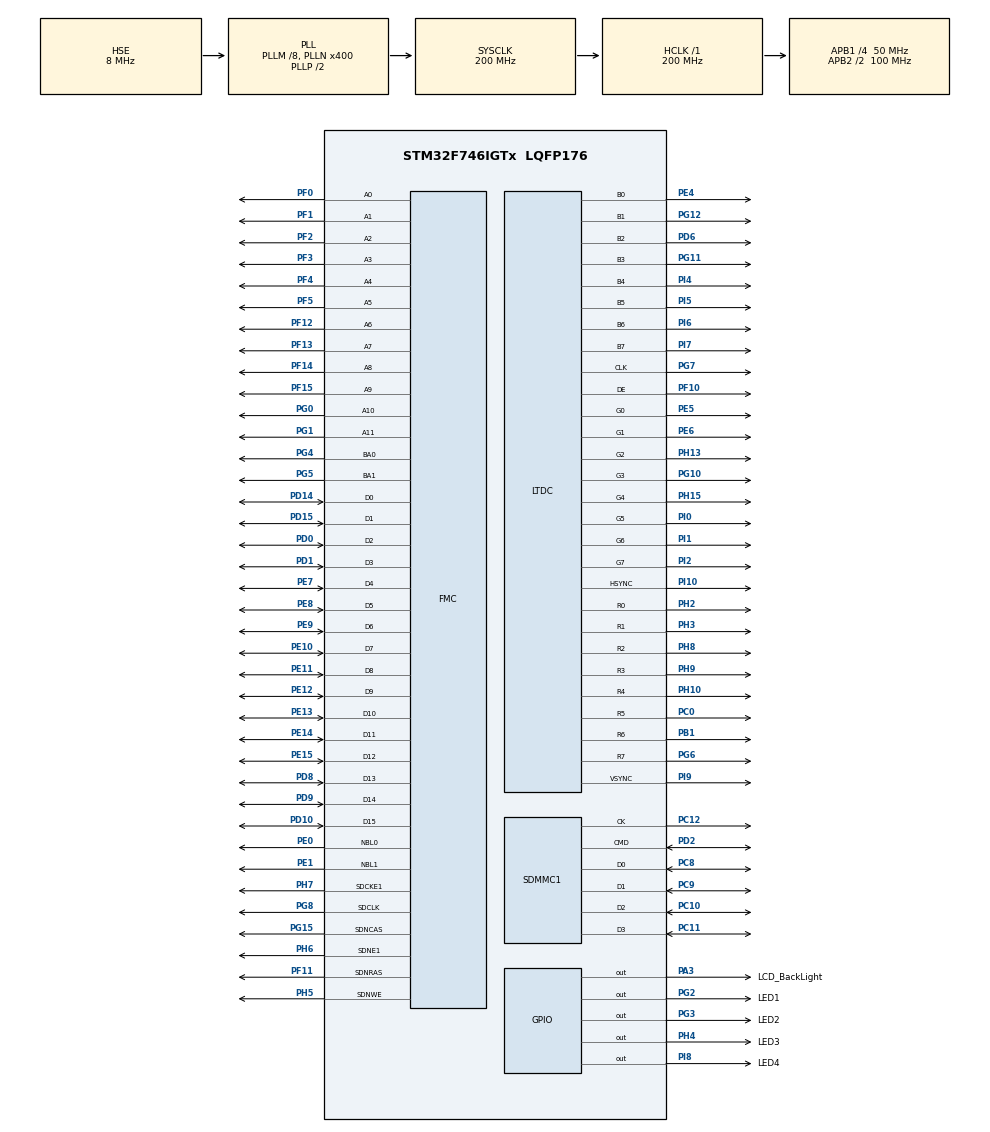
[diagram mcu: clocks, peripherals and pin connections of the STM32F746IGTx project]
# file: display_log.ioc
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CORTEX_M7.AccessPermission-Cortex_Memory_Protection_Unit_Region0_Settings=MPU_REGION_FULL_ACCESS
CORTEX_M7.BaseAddress-Cortex_Memory_Protection_Unit_Region0_Settings=0x20010000
CORTEX_M7.CPU_DCache=Enabled
CORTEX_M7.CPU_ICache=Enabled
CORTEX_M7.Enable-Cortex_Memory_Protection_Unit_Region0_Settings=MPU_REGION_ENABLE
CORTEX_M7.IsCacheable-Cortex_Memory_Protection_Unit_Region0_Settings=MPU_ACCESS_CACHEABLE
CORTEX_M7.MPU_Control=MPU_PRIVILEGED_DEFAULT
CORTEX_M7.Size-Cortex_Memory_Protection_Unit_Region0_Settings=MPU_REGION_SIZE_256KB
CORTEX_M7.SubRegionDisable-Cortex_Memory_Protection_Unit_Region0_Settings=0x0
DMA2D.ColorMode=DMA2D_OUTPUT_RGB565
Dma.MEMTOMEM.0.Direction=DMA_MEMORY_TO_MEMORY
Dma.MEMTOMEM.0.FIFOMode=DMA_FIFOMODE_ENABLE
Dma.MEMTOMEM.0.FIFOThreshold=DMA_FIFO_THRESHOLD_FULL
Dma.MEMTOMEM.0.Instance=DMA2_Stream0
Dma.MEMTOMEM.0.MemBurst=DMA_MBURST_SINGLE
Dma.MEMTOMEM.0.MemDataAlignment=DMA_MDATAALIGN_HALFWORD
Dma.MEMTOMEM.0.MemInc=DMA_MINC_ENABLE
Dma.MEMTOMEM.0.Mode=DMA_NORMAL
Dma.MEMTOMEM.0.PeriphBurst=DMA_PBURST_SINGLE
Dma.MEMTOMEM.0.PeriphDataAlignment=DMA_PDATAALIGN_HALFWORD
Dma.MEMTOMEM.0.PeriphInc=DMA_PINC_ENABLE
Dma.MEMTOMEM.0.Priority=DMA_PRIORITY_HIGH
Dma.Request0=MEMTOMEM
FATFS._MAX_SS=4096
FMC.CASLatency1=FMC_SDRAM_CAS_LATENCY_3
FMC.ExitSelfRefreshDelay1=7
FMC.LoadToActiveDelay1=2
FMC.RCDDelay1=2
FMC.RPDelay1=2
FMC.RPDelay2=2
FMC.ReadPipeDelay1=FMC_SDRAM_RPIPE_DELAY_1
FMC.ReadPipeDelay2=FMC_SDRAM_RPIPE_DELAY_1
FMC.RowBitsNumber1=FMC_SDRAM_ROW_BITS_NUM_12
FMC.RowCycleDelay1=6
FMC.RowCycleDelay2=6
FMC.SDClockPeriod1=FMC_SDRAM_CLOCK_PERIOD_2
FMC.SDClockPeriod2=FMC_SDRAM_CLOCK_PERIOD_2
FMC.SelfRefreshTime1=4
FMC.WriteRecoveryTime1=2
LTDC.ActiveH=600
LTDC.ActiveW=1024
LTDC.Alpha_L0=0xFF
LTDC.Alpha_L1=0
LTDC.BlendingFactor1_L0=LTDC_BLENDING_FACTOR1_PAxCA
LTDC.BlendingFactor1_L1=LTDC_BLENDING_FACTOR1_PAxCA
LTDC.BlendingFactor2_L0=LTDC_BLENDING_FACTOR2_PAxCA
LTDC.BlendingFactor2_L1=LTDC_BLENDING_FACTOR2_PAxCA
LTDC.FBStartAdress_L0=0xD0000000
LTDC.FBStartAdress_L1=0xD0200000
LTDC.HBP=140
LTDC.HFP=160
LTDC.HSync=20
LTDC.ImageHeight_L0=600
LTDC.ImageHeight_L1=600
LTDC.ImageWidth_L0=1024
LTDC.ImageWidth_L1=1024
LTDC.PixelFormat_L0=LTDC_PIXEL_FORMAT_RGB565
LTDC.PixelFormat_L1=LTDC_PIXEL_FORMAT_RGB565
LTDC.VBP=20
LTDC.VFP=12
LTDC.VSync=3
LTDC.WindowX1_L0=1024
LTDC.WindowX1_L1=1024
LTDC.WindowY1_L0=600
LTDC.WindowY1_L1=600
Mcu.Family=STM32F7
Mcu.Name=STM32F746IGTx
Mcu.Package=LQFP176
NVIC.PriorityGroup=NVIC_PRIORITYGROUP_4
PA3.GPIO_Label=LCD_BackLight
PA3.Signal=GPIO_Output
PB1.GPIO_Speed=GPIO_SPEED_FREQ_VERY_HIGH
PB1.Mode=RGB888
PB1.Signal=LTDC_R6
PC0.GPIO_Speed=GPIO_SPEED_FREQ_VERY_HIGH
PC0.Mode=RGB888
PC0.Signal=LTDC_R5
PC10.Mode=SD_4_bits_Wide_bus
PC10.Signal=SDMMC1_D2
PC11.Mode=SD_4_bits_Wide_bus
PC11.Signal=SDMMC1_D3
PC12.Mode=SD_4_bits_Wide_bus
PC12.Signal=SDMMC1_CK
PC8.Mode=SD_4_bits_Wide_bus
PC8.Signal=SDMMC1_D0
PC9.Mode=SD_4_bits_Wide_bus
PC9.Signal=SDMMC1_D1
PD0.Signal=FMC_D2_DA2
PD1.Signal=FMC_D3_DA3
PD10.Signal=FMC_D15_DA15
PD14.Signal=FMC_D0_DA0
PD15.Signal=FMC_D1_DA1
PD2.Mode=SD_4_bits_Wide_bus
PD2.Signal=SDMMC1_CMD
PD6.GPIO_Speed=GPIO_SPEED_FREQ_VERY_HIGH
PD6.Mode=RGB888
PD6.Signal=LTDC_B2
PD8.Signal=FMC_D13_DA13
PD9.Signal=FMC_D14_DA14
PE0.Signal=FMC_NBL0
PE1.Signal=FMC_NBL1
PE10.Signal=FMC_D7_DA7
PE11.Signal=FMC_D8_DA8
PE12.Signal=FMC_D9_DA9
PE13.Signal=FMC_D10_DA10
PE14.Signal=FMC_D11_DA11
PE15.Signal=FMC_D12_DA12
PE4.GPIO_Speed=GPIO_SPEED_FREQ_VERY_HIGH
PE4.Mode=RGB888
PE4.Signal=LTDC_B0
PE5.GPIO_Speed=GPIO_SPEED_FREQ_VERY_HIGH
PE5.Mode=RGB888
PE5.Signal=LTDC_G0
PE6.GPIO_Speed=GPIO_SPEED_FREQ_VERY_HIGH
PE6.Mode=RGB888
PE6.Signal=LTDC_G1
PE7.Signal=FMC_D4_DA4
PE8.Signal=FMC_D5_DA5
PE9.Signal=FMC_D6_DA6
PF0.Signal=FMC_A0
PF1.Signal=FMC_A1
PF10.GPIO_Speed=GPIO_SPEED_FREQ_VERY_HIGH
PF10.Mode=RGB888
PF10.Signal=LTDC_DE
PF11.Signal=FMC_SDNRAS
PF12.Signal=FMC_A6
PF13.Signal=FMC_A7
PF14.Signal=FMC_A8
PF15.Signal=FMC_A9
PF2.Signal=FMC_A2
PF3.Signal=FMC_A3
PF4.Signal=FMC_A4
PF5.Signal=FMC_A5
PG0.Signal=FMC_A10
PG1.Signal=FMC_A11
PG10.GPIO_Speed=GPIO_SPEED_FREQ_VERY_HIGH
PG10.Mode=RGB888
PG10.Signal=LTDC_G3
PG11.GPIO_Speed=GPIO_SPEED_FREQ_VERY_HIGH
PG11.Mode=RGB888
PG11.Signal=LTDC_B3
PG12.GPIO_Speed=GPIO_SPEED_FREQ_VERY_HIGH
PG12.Mode=RGB888
PG12.Signal=LTDC_B1
PG15.Signal=FMC_SDNCAS
PG2.GPIO_Label=LED1
PG2.Signal=GPIO_Output
PG3.GPIO_Label=LED2
PG3.Signal=GPIO_Output
PG4.Signal=FMC_A14_BA0
PG5.Signal=FMC_A15_BA1
PG6.GPIO_Speed=GPIO_SPEED_FREQ_VERY_HIGH
PG6.Mode=RGB888
PG6.Signal=LTDC_R7
PG7.GPIO_Speed=GPIO_SPEED_FREQ_VERY_HIGH
PG7.Mode=RGB888
PG7.Signal=LTDC_CLK
PG8.Signal=FMC_SDCLK
PH0/OSC_IN.Mode=HSE-External-Oscillator
PH0/OSC_IN.Signal=RCC_OSC_IN
PH1/OSC_OUT.Mode=HSE-External-Oscillator
PH1/OSC_OUT.Signal=RCC_OSC_OUT
PH10.GPIO_Speed=GPIO_SPEED_FREQ_VERY_HIGH
PH10.Mode=RGB888
PH10.Signal=LTDC_R4
PH13.GPIO_Speed=GPIO_SPEED_FREQ_VERY_HIGH
PH13.Mode=RGB888
PH13.Signal=LTDC_G2
PH15.GPIO_Speed=GPIO_SPEED_FREQ_VERY_HIGH
PH15.Mode=RGB888
PH15.Signal=LTDC_G4
PH2.GPIO_Speed=GPIO_SPEED_FREQ_VERY_HIGH
PH2.Mode=RGB888
PH2.Signal=LTDC_R0
PH3.GPIO_Speed=GPIO_SPEED_FREQ_VERY_HIGH
PH3.Mode=RGB888
PH3.Signal=LTDC_R1
PH4.GPIO_Label=LED3
PH4.Signal=GPIO_Output
PH5.Signal=FMC_SDNWE
PH6.Mode=SdramChipSelect2_1
PH6.Signal=FMC_SDNE1
PH7.Mode=SdramChipSelect2_1
PH7.Signal=FMC_SDCKE1
PH8.GPIO_Speed=GPIO_SPEED_FREQ_VERY_HIGH
PH8.Mode=RGB888
PH8.Signal=LTDC_R2
PH9.GPIO_Speed=GPIO_SPEED_FREQ_VERY_HIGH
PH9.Mode=RGB888
PH9.Signal=LTDC_R3
PI0.GPIO_Speed=GPIO_SPEED_FREQ_VERY_HIGH
PI0.Mode=RGB888
PI0.Signal=LTDC_G5
PI1.GPIO_Speed=GPIO_SPEED_FREQ_VERY_HIGH
PI1.Mode=RGB888
PI1.Signal=LTDC_G6
PI10.GPIO_Speed=GPIO_SPEED_FREQ_VERY_HIGH
PI10.Mode=RGB888
PI10.Signal=LTDC_HSYNC
PI2.GPIO_Speed=GPIO_SPEED_FREQ_VERY_HIGH
PI2.Mode=RGB888
PI2.Signal=LTDC_G7
PI4.GPIO_Speed=GPIO_SPEED_FREQ_VERY_HIGH
PI4.Mode=RGB888
PI4.Signal=LTDC_B4
PI5.GPIO_Speed=GPIO_SPEED_FREQ_VERY_HIGH
PI5.Mode=RGB888
PI5.Signal=LTDC_B5
PI6.GPIO_Speed=GPIO_SPEED_FREQ_VERY_HIGH
PI6.Mode=RGB888
PI6.Signal=LTDC_B6
PI7.GPIO_Speed=GPIO_SPEED_FREQ_VERY_HIGH
PI7.Mode=RGB888
PI7.Signal=LTDC_B7
PI8.GPIO_Label=LED4
PI8.Signal=GPIO_Output
PI9.GPIO_Speed=GPIO_SPEED_FREQ_VERY_HIGH
PI9.Mode=RGB888
PI9.Signal=LTDC_VSYNC
ProjectManager.HeapSize=0x200
ProjectManager.StackSize=0x400
ProjectManager.TargetToolchain=SW4STM32
RCC.AHBFreq_Value=200000000
RCC.APB1CLKDivider=RCC_HCLK_DIV4
RCC.APB1Freq_Value=50000000
RCC.APB1TimFreq_Value=100000000
RCC.APB2CLKDivider=RCC_HCLK_DIV2
RCC.APB2Freq_Value=100000000
RCC.APB2TimFreq_Value=200000000
RCC.CortexFreq_Value=200000000
RCC.HCLKFreq_Value=200000000
RCC.HSE_VALUE=8000000
RCC.HSI_VALUE=16000000
RCC.LSE_VALUE=32768
RCC.PLLM=8
RCC.PLLN=400
RCC.PLLQ=8
RCC.PLLSAIR=3
RCC.PLLSourceVirtual=RCC_PLLSOURCE_HSE
RCC.SDMMCClockSelection=RCC_SDMMC1CLKSOURCE_CLK48
RCC.SYSCLKFreq_VALUE=200000000
RCC.SYSCLKSource=RCC_SYSCLKSOURCE_PLLCLK
RCC.USBFreq_Value=50000000
RCC.VCOOutputFreq_Value=400000000
SDMMC1.ClockDiv=5
SH.FMC_A0.0=FMC_A0,12b-sda1
SH.FMC_A1.0=FMC_A1,12b-sda1
SH.FMC_A10.0=FMC_A10,12b-sda1
SH.FMC_A11.0=FMC_A11,12b-sda1
SH.FMC_A14_BA0.0=FMC_BA0,FourSdramBanks1
SH.FMC_A15_BA1.0=FMC_BA1,FourSdramBanks1
SH.FMC_A2.0=FMC_A2,12b-sda1
SH.FMC_A3.0=FMC_A3,12b-sda1
SH.FMC_A4.0=FMC_A4,12b-sda1
SH.FMC_A5.0=FMC_A5,12b-sda1
SH.FMC_A6.0=FMC_A6,12b-sda1
SH.FMC_A7.0=FMC_A7,12b-sda1
SH.FMC_A8.0=FMC_A8,12b-sda1
SH.FMC_A9.0=FMC_A9,12b-sda1
SH.FMC_D0_DA0.0=FMC_D0,sd-16b-d1
SH.FMC_D10_DA10.0=FMC_D10,sd-16b-d1
SH.FMC_D11_DA11.0=FMC_D11,sd-16b-d1
SH.FMC_D12_DA12.0=FMC_D12,sd-16b-d1
SH.FMC_D13_DA13.0=FMC_D13,sd-16b-d1
SH.FMC_D14_DA14.0=FMC_D14,sd-16b-d1
SH.FMC_D15_DA15.0=FMC_D15,sd-16b-d1
SH.FMC_D1_DA1.0=FMC_D1,sd-16b-d1
SH.FMC_D2_DA2.0=FMC_D2,sd-16b-d1
SH.FMC_D3_DA3.0=FMC_D3,sd-16b-d1
SH.FMC_D4_DA4.0=FMC_D4,sd-16b-d1
SH.FMC_D5_DA5.0=FMC_D5,sd-16b-d1
SH.FMC_D6_DA6.0=FMC_D6,sd-16b-d1
SH.FMC_D7_DA7.0=FMC_D7,sd-16b-d1
SH.FMC_D8_DA8.0=FMC_D8,sd-16b-d1
SH.FMC_D9_DA9.0=FMC_D9,sd-16b-d1
SH.FMC_NBL0.0=FMC_NBL0,Sd2ByteEnable1
SH.FMC_NBL1.0=FMC_NBL1,Sd2ByteEnable1
SH.FMC_SDCLK.0=FMC_SDCLK,12b-sda1
SH.FMC_SDNCAS.0=FMC_SDNCAS,12b-sda1
SH.FMC_SDNRAS.0=FMC_SDNRAS,12b-sda1
SH.FMC_SDNWE.0=FMC_SDNWE,12b-sda1
VP_DMA2D_VS_DMA2D.Mode=DMA2D_Activate
VP_FATFS_VS_SDIO.Mode=SDIO
board=STM32F746I

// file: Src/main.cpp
/* USER CODE BEGIN Header */
/**
 ******************************************************************************
 * @file           : main.c
 * @brief          : Main program body
 ******************************************************************************
 ** This notice applies to any and all portions of this file
 * that are not between comment pairs USER CODE BEGIN and
 * USER CODE END. Other portions of this file, whether
 * inserted by the user or by software development tools
 * are owned by their respective copyright owners.
 *
 * COPYRIGHT(c) 2019 STMicroelectronics
 *
 * Redistribution and use in source and binary forms, with or without modification,
 * are permitted provided that the following conditions are met:
 *   1. Redistributions of source code must retain the above copyright notice,
 *      this list of conditions and the following disclaimer.
 *   2. Redistributions in binary form must reproduce the above copyright notice,
 *      this list of conditions and the following disclaimer in the documentation
 *      and/or other materials provided with the distribution.
 *   3. Neither the name of STMicroelectronics nor the names of its contributors
 *      may be used to endorse or promote products derived from this software
 *      without specific prior written permission.
 *
 * THIS SOFTWARE IS PROVIDED BY THE COPYRIGHT HOLDERS AND CONTRIBUTORS "AS IS"
 * AND ANY EXPRESS OR IMPLIED WARRANTIES, INCLUDING, BUT NOT LIMITED TO, THE
 * IMPLIED WARRANTIES OF MERCHANTABILITY AND FITNESS FOR A PARTICULAR PURPOSE ARE
 * DISCLAIMED. IN NO EVENT SHALL THE COPYRIGHT HOLDER OR CONTRIBUTORS BE LIABLE
 * FOR ANY DIRECT, INDIRECT, INCIDENTAL, SPECIAL, EXEMPLARY, OR CONSEQUENTIAL
 * DAMAGES (INCLUDING, BUT NOT LIMITED TO, PROCUREMENT OF SUBSTITUTE GOODS OR
 * SERVICES; LOSS OF USE, DATA, OR PROFITS; OR BUSINESS INTERRUPTION) HOWEVER
 * CAUSED AND ON ANY THEORY OF LIABILITY, WHETHER IN CONTRACT, STRICT LIABILITY,
 * OR TORT (INCLUDING NEGLIGENCE OR OTHERWISE) ARISING IN ANY WAY OUT OF THE USE
 * OF THIS SOFTWARE, EVEN IF ADVISED OF THE POSSIBILITY OF SUCH DAMAGE.
 *
 ******************************************************************************
 */
/* USER CODE END Header */

#include "main.h"
#include "dma.h"
#include "dma2d.h"
#include "fatfs.h"
#include "ltdc.h"
#include "sdmmc.h"
#include "gpio.h"
#include "fmc.h"

/* USER CODE BEGIN Includes */
extern "C" {
#include "stm32746g_sdram.h"
#include "stm32746g_LCD.h"
#include "lcd_log.h"
#include "stm32f7xx_hal_ltdc.h"
}
//#include "Window.h"
#include "plot.h"
/* USER CODE END Includes */

/* USER CODE BEGIN PV */
/* Private variables ---------------------------------------------------------*/

/* USER CODE END PV */

void SystemClock_Config(void);
static void MPU_Config(void);
/* USER CODE BEGIN PFP */
/* Private function prototypes -----------------------------------------------*/

/* USER CODE END PFP */

int main(void)
{
  /* USER CODE BEGIN 1 */
	int line = 5;
//	uint32_t x = 3445;
//	uint32_t x_1 = 65547;
//	uint64_t x_64 = 46534564;
//	uint64_t t = __SMLALD(x, x_1, x_64);
//	uint64_t t2 = (x * x_1) + x_64;
  /* USER CODE END 1 */

  /* MPU Configuration--------------------------------------------------------*/
  MPU_Config();

  /* Enable I-Cache---------------------------------------------------------*/
  SCB_EnableICache();

  /* Enable D-Cache---------------------------------------------------------*/
  SCB_EnableDCache();

  /* MCU Configuration--------------------------------------------------------*/

  /* Reset of all peripherals, Initializes the Flash interface and the Systick. */
  HAL_Init();

  /* Configure the system clock */
  SystemClock_Config();

  /* Initialize all configured peripherals */
  MX_GPIO_Init();
  MX_DMA_Init();
  MX_DMA2D_Init();
  MX_FMC_Init();
  MX_LTDC_Init();
  MX_SDMMC1_SD_Init();
  MX_FATFS_Init();
  /* USER CODE BEGIN 2 */
	/* Initialize the SDRAM */
	BSP_SDRAM_Init();

	/* Initialize the LCD */
	BSP_LCD_Init();

	/* Clear the LCD Background layer */
	BSP_LCD_SetLayerVisible(1,DISABLE);

	/* Set LCD Foreground Layer  */
	/*BSP_LCD_SelectLayer(1);
	LCD_LOG_Init();
	BSP_LCD_SetFont(&LCD_DEFAULT_FONT);

	BSP_LCD_SelectLayer(0);

	//	BSP_LCD_Clear(LCD_COLOR_BLACK);
	BSP_LCD_SetFont(&LCD_DEFAULT_FONT);*/

	/* Initialize LCD Log module */
//	LCD_LOG_Init();

	/* Show Header and Footer texts */
//	LCD_LOG_SetHeader((uint8_t *)"LOG Messages");
	Drawable *dr = new Drawable();
//	BSP_LCD_SelectLayer(0);
//	BSP_LCD_SetFont(&Font20);

  /* USER CODE END 2 */

  /* Infinite loop */
  /* USER CODE BEGIN WHILE */
//	Window *win = new Window(Point2d(100, 100), 800, 500);
	plot *win = new plot();
	win->set_size(800, 300);
	Point2d pos;
	pos.x = 100;
	pos.y = 90;
	int8_t dx = 2;
	int8_t dy = 1;
	while (1)
	{
		pos.x += dx;
		if ((pos.x + win->width + win->thickness_border) > 1024
				|| ((pos.x - win->thickness_border) < 0)){
			dx *= -1;
			pos.x += dx;
		}

		pos.y += dy;
		if ((pos.y + win->height + win->thickness_border) > 600
				|| ((pos.y - win->thickness_border) < 0)){
			dy *= -1;
			pos.y += dy;
		}

		win->set_pos(pos);
		win->draw();
		dr->swap_buffers();
    /* USER CODE END WHILE */

    /* USER CODE BEGIN 3 */
//		LCD_UsrLog ("  Hello World ... %d\n",line);
//		LCD_ErrLog ("  Hello World ... %d\n",line);
//		LCD_DbgLog ("  Hello World ... %d\n",line++);
//		HAL_Delay(1000);
	}
  /* USER CODE END 3 */
}

void SystemClock_Config(void)
{
  RCC_OscInitTypeDef RCC_OscInitStruct = {0};
  RCC_ClkInitTypeDef RCC_ClkInitStruct = {0};
  RCC_PeriphCLKInitTypeDef PeriphClkInitStruct = {0};

  /**Configure the main internal regulator output voltage
  */
  __HAL_RCC_PWR_CLK_ENABLE();
  __HAL_PWR_VOLTAGESCALING_CONFIG(PWR_REGULATOR_VOLTAGE_SCALE1);
  /**Initializes the CPU, AHB and APB busses clocks
  */
  RCC_OscInitStruct.OscillatorType = RCC_OSCILLATORTYPE_HSE;
  RCC_OscInitStruct.HSEState = RCC_HSE_ON;
  RCC_OscInitStruct.PLL.PLLState = RCC_PLL_ON;
  RCC_OscInitStruct.PLL.PLLSource = RCC_PLLSOURCE_HSE;
  RCC_OscInitStruct.PLL.PLLM = 8;
  RCC_OscInitStruct.PLL.PLLN = 400;
  RCC_OscInitStruct.PLL.PLLP = RCC_PLLP_DIV2;
  RCC_OscInitStruct.PLL.PLLQ = 8;
  if (HAL_RCC_OscConfig(&RCC_OscInitStruct) != HAL_OK)
  {
    Error_Handler();
  }
  /**Activate the Over-Drive mode
  */
  if (HAL_PWREx_EnableOverDrive() != HAL_OK)
  {
    Error_Handler();
  }
  /**Initializes the CPU, AHB and APB busses clocks
  */
  RCC_ClkInitStruct.ClockType = RCC_CLOCKTYPE_HCLK|RCC_CLOCKTYPE_SYSCLK
                              |RCC_CLOCKTYPE_PCLK1|RCC_CLOCKTYPE_PCLK2;
  RCC_ClkInitStruct.SYSCLKSource = RCC_SYSCLKSOURCE_PLLCLK;
  RCC_ClkInitStruct.AHBCLKDivider = RCC_SYSCLK_DIV1;
  RCC_ClkInitStruct.APB1CLKDivider = RCC_HCLK_DIV4;
  RCC_ClkInitStruct.APB2CLKDivider = RCC_HCLK_DIV2;

  if (HAL_RCC_ClockConfig(&RCC_ClkInitStruct, FLASH_LATENCY_6) != HAL_OK)
  {
    Error_Handler();
  }
  PeriphClkInitStruct.PeriphClockSelection = RCC_PERIPHCLK_LTDC|RCC_PERIPHCLK_SDMMC1
                              |RCC_PERIPHCLK_CLK48;
  PeriphClkInitStruct.PLLSAI.PLLSAIN = 192;
  PeriphClkInitStruct.PLLSAI.PLLSAIR = 3;
  PeriphClkInitStruct.PLLSAI.PLLSAIQ = 2;
  PeriphClkInitStruct.PLLSAI.PLLSAIP = RCC_PLLSAIP_DIV2;
  PeriphClkInitStruct.PLLSAIDivQ = 1;
  PeriphClkInitStruct.PLLSAIDivR = RCC_PLLSAIDIVR_2;
  PeriphClkInitStruct.Clk48ClockSelection = RCC_CLK48SOURCE_PLL;
  PeriphClkInitStruct.Sdmmc1ClockSelection = RCC_SDMMC1CLKSOURCE_CLK48;
  if (HAL_RCCEx_PeriphCLKConfig(&PeriphClkInitStruct) != HAL_OK)
  {
    Error_Handler();
  }
}

/* MPU Configuration */

void MPU_Config(void)
{
  MPU_Region_InitTypeDef MPU_InitStruct = {0};

  /* Disables the MPU */
  HAL_MPU_Disable();
  /**Initializes and configures the Region and the memory to be protected
  */
  MPU_InitStruct.Enable = MPU_REGION_ENABLE;
  MPU_InitStruct.Number = MPU_REGION_NUMBER0;
  MPU_InitStruct.BaseAddress = 0x20010000;
  MPU_InitStruct.Size = MPU_REGION_SIZE_256KB;
  MPU_InitStruct.SubRegionDisable = 0x0;
  MPU_InitStruct.TypeExtField = MPU_TEX_LEVEL0;
  MPU_InitStruct.AccessPermission = MPU_REGION_FULL_ACCESS;
  MPU_InitStruct.DisableExec = MPU_INSTRUCTION_ACCESS_ENABLE;
  MPU_InitStruct.IsShareable = MPU_ACCESS_NOT_SHAREABLE;
  MPU_InitStruct.IsCacheable = MPU_ACCESS_CACHEABLE;
  MPU_InitStruct.IsBufferable = MPU_ACCESS_NOT_BUFFERABLE;

  HAL_MPU_ConfigRegion(&MPU_InitStruct);
  /* Enables the MPU */
  HAL_MPU_Enable(MPU_PRIVILEGED_DEFAULT);

}

void Error_Handler(void)
{
}

/************************ (C) COPYRIGHT STMicroelectronics *****END OF FILE****/
